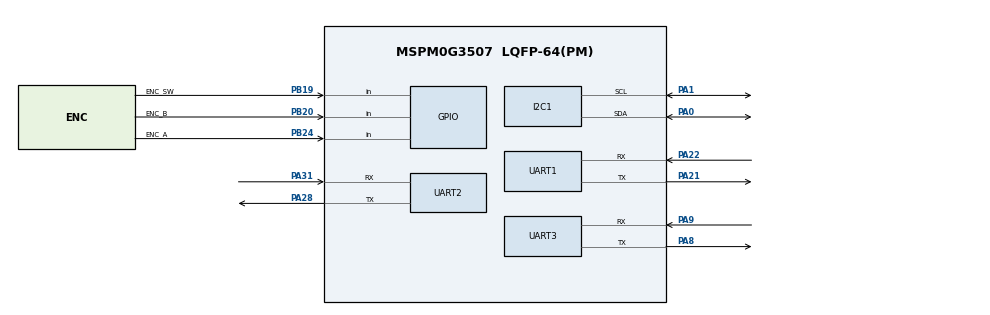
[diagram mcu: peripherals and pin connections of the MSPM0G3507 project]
/**
 * @cliArgs --device "MSPM0G350X" --part "Default" --package "LQFP-64(PM)" --product "mspm0_sdk@2.10.00.04"
 * @v2CliArgs --device "MSPM0G3507" --package "LQFP-64(PM)" --product "mspm0_sdk@2.10.00.04"
 * @versions {"tool":"1.26.2+4477"}
 */

/* 仅保留旋钮编码器、数据串口和 Emm_V5 电机串口。 */
const GPIO   = scripting.addModule("/ti/driverlib/GPIO", {}, false);
const GPIO1  = GPIO.addInstance();
const Board  = scripting.addModule("/ti/driverlib/Board", {}, false);
const I2C    = scripting.addModule("/ti/driverlib/I2C", {}, false);
const I2C1   = I2C.addInstance();
const SYSCTL = scripting.addModule("/ti/driverlib/SYSCTL");
const UART   = scripting.addModule("/ti/driverlib/UART", {}, false);
const UART1  = UART.addInstance();
const UART2  = UART.addInstance();
const UART3  = UART.addInstance();

GPIO1.$name                              = "Bianma";
GPIO1.associatedPins.create(3);
GPIO1.associatedPins[0].$name            = "ENC_A";
GPIO1.associatedPins[0].direction        = "INPUT";
GPIO1.associatedPins[0].internalResistor = "PULL_UP";
/* 地猛星排针可直接连接：PB24。 */
GPIO1.associatedPins[0].pin.$assign      = "PB24";
GPIO1.associatedPins[1].$name            = "ENC_B";
GPIO1.associatedPins[1].direction        = "INPUT";
GPIO1.associatedPins[1].internalResistor = "PULL_UP";
/* 地猛星排针可直接连接：PB20。 */
GPIO1.associatedPins[1].pin.$assign      = "PB20";
GPIO1.associatedPins[2].$name            = "ENC_SW";
GPIO1.associatedPins[2].direction        = "INPUT";
GPIO1.associatedPins[2].internalResistor = "PULL_UP";
/* 地猛星排针可直接连接：PB19。 */
GPIO1.associatedPins[2].pin.$assign      = "PB19";

/* 0.96英寸四针OLED：I2C0，PA0-SDA，PA1-SCL。 */
I2C1.$name                             = "OLED";
I2C1.basicEnableController             = true;
I2C1.advDigitalGlitchFilter            = "CLOCKS_1";
I2C1.advControllerRXFIFOTRIG           = "BYTES_8";
I2C1.advControllerTXFIFOTRIG           = "BYTES_7";
I2C1.enableDMAEvent1                   = false;
I2C1.enableDMAEvent2                   = false;
I2C1.peripheral.$assign                = "I2C0";
I2C1.peripheral.sdaPin.$assign         = "PA0";
I2C1.peripheral.sclPin.$assign         = "PA1";
I2C1.sdaPinConfig.$name                = "OLED_SDA_PIN";
I2C1.sdaPinConfig.hideOutputInversion  = scripting.forceWrite(false);
I2C1.sdaPinConfig.onlyInternalResistor = scripting.forceWrite(false);
I2C1.sdaPinConfig.passedPeripheralType = scripting.forceWrite("Digital");
I2C1.sdaPinConfig.enableConfig         = true;
I2C1.sclPinConfig.$name                = "OLED_SCL_PIN";
I2C1.sclPinConfig.hideOutputInversion  = scripting.forceWrite(false);
I2C1.sclPinConfig.onlyInternalResistor = scripting.forceWrite(false);
I2C1.sclPinConfig.passedPeripheralType = scripting.forceWrite("Digital");
I2C1.sclPinConfig.enableConfig         = true;

SYSCTL.forceDefaultClkConfig = true;
SYSCTL.clockTreeEn           = true;

/* 外部数据通信串口：UART2，PA21-TX，PA22-RX。 */
UART1.$name                            = "PRINT";
UART1.targetBaudRate                   = 115200;
UART1.rxFifoThreshold                  = "DL_UART_RX_FIFO_LEVEL_ONE_ENTRY";
UART1.peripheral.$assign               = "UART2";
UART1.peripheral.txPin.$assign         = "PA21";
UART1.peripheral.rxPin.$assign         = "PA22";
UART1.txPinConfig.direction            = scripting.forceWrite("OUTPUT");
UART1.txPinConfig.hideOutputInversion  = scripting.forceWrite(false);
UART1.txPinConfig.onlyInternalResistor = scripting.forceWrite(false);
UART1.txPinConfig.passedPeripheralType = scripting.forceWrite("Digital");
UART1.txPinConfig.$name                = "PRINT_TX_PIN";
UART1.rxPinConfig.hideOutputInversion  = scripting.forceWrite(false);
UART1.rxPinConfig.onlyInternalResistor = scripting.forceWrite(false);
UART1.rxPinConfig.passedPeripheralType = scripting.forceWrite("Digital");
UART1.rxPinConfig.$name                = "PRINT_RX_PIN";

/* 已验证可驱动 Emm_V5：UART0，PA28-TX，PA31-RX。 */
UART2.$name                            = "MOTOR_UART";
UART2.targetBaudRate                   = 115200;
UART2.peripheral.$assign               = "UART0";
UART2.peripheral.txPin.$assign         = "PA28";
UART2.peripheral.rxPin.$assign         = "PA31";
UART2.txPinConfig.direction            = scripting.forceWrite("OUTPUT");
UART2.txPinConfig.hideOutputInversion  = scripting.forceWrite(false);
UART2.txPinConfig.onlyInternalResistor = scripting.forceWrite(false);
UART2.txPinConfig.passedPeripheralType = scripting.forceWrite("Digital");
UART2.txPinConfig.$name                = "MOTOR_UART_TX_PIN";
UART2.rxPinConfig.hideOutputInversion  = scripting.forceWrite(false);
UART2.rxPinConfig.onlyInternalResistor = scripting.forceWrite(false);
UART2.rxPinConfig.passedPeripheralType = scripting.forceWrite("Digital");
UART2.rxPinConfig.$name                = "MOTOR_UART_RX_PIN";

/* llm-pid-tuner 专用调参串口：UART1，PA8-TX，PA9-RX，115200。 */
UART3.$name                            = "LLM_UART";
UART3.targetBaudRate                   = 115200;
UART3.rxFifoThreshold                  = "DL_UART_RX_FIFO_LEVEL_ONE_ENTRY";
UART3.peripheral.$assign               = "UART1";
UART3.peripheral.txPin.$assign         = "PA8";
UART3.peripheral.rxPin.$assign         = "PA9";
UART3.txPinConfig.direction            = scripting.forceWrite("OUTPUT");
UART3.txPinConfig.hideOutputInversion  = scripting.forceWrite(false);
UART3.txPinConfig.onlyInternalResistor = scripting.forceWrite(false);
UART3.txPinConfig.passedPeripheralType = scripting.forceWrite("Digital");
UART3.txPinConfig.$name                = "LLM_UART_TX_PIN";
UART3.rxPinConfig.hideOutputInversion  = scripting.forceWrite(false);
UART3.rxPinConfig.onlyInternalResistor = scripting.forceWrite(false);
UART3.rxPinConfig.passedPeripheralType = scripting.forceWrite("Digital");
UART3.rxPinConfig.$name                = "LLM_UART_RX_PIN";

UART1.peripheral.$suggestSolution = "UART2";
UART2.peripheral.$suggestSolution = "UART0";
UART3.peripheral.$suggestSolution = "UART1";
Board.peripheral.$suggestSolution          = "DEBUGSS";
Board.peripheral.swclkPin.$suggestSolution = "PA20";
Board.peripheral.swdioPin.$suggestSolution = "PA19";
